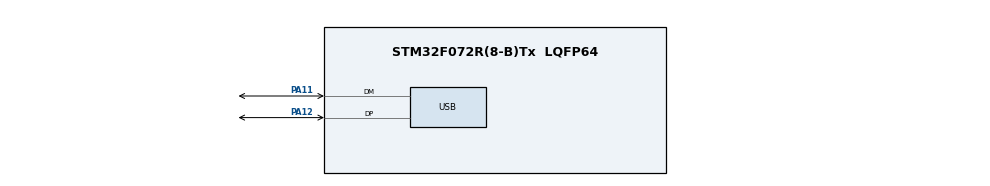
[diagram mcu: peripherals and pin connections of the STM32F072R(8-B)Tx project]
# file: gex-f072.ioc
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FREERTOS.Tasks01=defaultTask,0,128,StartDefaultTask,Default,NULL
Mcu.Family=STM32F0
Mcu.Name=STM32F072R(8-B)Tx
Mcu.Package=LQFP64
NVIC.TIM1_BRK_UP_TRG_COM_IRQn=true\:0\:0\:false\:false\:true\:false\:false
NVIC.TimeBase=TIM1_BRK_UP_TRG_COM_IRQn
NVIC.TimeBaseIP=TIM1
PA11.Mode=Device
PA11.Signal=USB_DM
PA12.Mode=Device
PA12.Signal=USB_DP
PA13.Mode=Serial_Wire
PA13.Signal=SYS_SWDIO
PA14.Mode=Serial_Wire
PA14.Signal=SYS_SWCLK
PF0-OSC_IN.Mode=HSE-External-Clock-Source
PF0-OSC_IN.Signal=RCC_OSC_IN
ProjectManager.HeapSize=0x200
ProjectManager.StackSize=0x400
ProjectManager.TargetToolchain=Makefile
RCC.AHBFreq_Value=48000000
RCC.APB1Freq_Value=48000000
RCC.APB1TimFreq_Value=48000000
RCC.HCLKFreq_Value=48000000
RCC.PLLMUL=RCC_PLL_MUL6
RCC.PLLSourceVirtual=RCC_PLLSOURCE_HSE
RCC.SYSCLKFreq_VALUE=48000000
RCC.SYSCLKSource=RCC_SYSCLKSOURCE_PLLCLK
VP_FREERTOS_VS_ENABLE.Mode=Enabled
VP_SYS_VS_tim1.Mode=TIM1
board=gex-f072

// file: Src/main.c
/**
  ******************************************************************************
  * File Name          : main.c
  * Description        : Main program body
  ******************************************************************************
  * This notice applies to any and all portions of this file
  * that are not between comment pairs USER CODE BEGIN and
  * USER CODE END. Other portions of this file, whether
  * inserted by the user or by software development tools
  * are owned by their respective copyright owners.
  *
  * Copyright (c) 2017 STMicroelectronics International N.V.
  * All rights reserved.
  *
  * Redistribution and use in source and binary forms, with or without
  * modification, are permitted, provided that the following conditions are met:
  *
  * 1. Redistribution of source code must retain the above copyright notice,
  *    this list of conditions and the following disclaimer.
  * 2. Redistributions in binary form must reproduce the above copyright notice,
  *    this list of conditions and the following disclaimer in the documentation
  *    and/or other materials provided with the distribution.
  * 3. Neither the name of STMicroelectronics nor the names of other
  *    contributors to this software may be used to endorse or promote products
  *    derived from this software without specific written permission.
  * 4. This software, including modifications and/or derivative works of this
  *    software, must execute solely and exclusively on microcontroller or
  *    microprocessor devices manufactured by or for STMicroelectronics.
  * 5. Redistribution and use of this software other than as permitted under
  *    this license is void and will automatically terminate your rights under
  *    this license.
  *
  * THIS SOFTWARE IS PROVIDED BY STMICROELECTRONICS AND CONTRIBUTORS "AS IS"
  * AND ANY EXPRESS, IMPLIED OR STATUTORY WARRANTIES, INCLUDING, BUT NOT
  * LIMITED TO, THE IMPLIED WARRANTIES OF MERCHANTABILITY, FITNESS FOR A
  * PARTICULAR PURPOSE AND NON-INFRINGEMENT OF THIRD PARTY INTELLECTUAL PROPERTY
  * RIGHTS ARE DISCLAIMED TO THE FULLEST EXTENT PERMITTED BY LAW. IN NO EVENT
  * SHALL STMICROELECTRONICS OR CONTRIBUTORS BE LIABLE FOR ANY DIRECT, INDIRECT,
  * INCIDENTAL, SPECIAL, EXEMPLARY, OR CONSEQUENTIAL DAMAGES (INCLUDING, BUT NOT
  * LIMITED TO, PROCUREMENT OF SUBSTITUTE GOODS OR SERVICES; LOSS OF USE, DATA,
  * OR PROFITS; OR BUSINESS INTERRUPTION) HOWEVER CAUSED AND ON ANY THEORY OF
  * LIABILITY, WHETHER IN CONTRACT, STRICT LIABILITY, OR TORT (INCLUDING
  * NEGLIGENCE OR OTHERWISE) ARISING IN ANY WAY OUT OF THE USE OF THIS SOFTWARE,
  * EVEN IF ADVISED OF THE POSSIBILITY OF SUCH DAMAGE.
  *
  ******************************************************************************
  */

#include "main.h"
#include "stm32f0xx_hal.h"
#include "cmsis_os.h"
#include <stdbool.h>

/* USER CODE BEGIN Includes */
#include "gex_hooks.h"
/* USER CODE END Includes */

/* USER CODE BEGIN PV */
/* Private variables ---------------------------------------------------------*/

/* USER CODE END PV */

void SystemClock_Config(void);
void MX_FREERTOS_Init(void);

/* USER CODE BEGIN PFP */
/* Private function prototypes -----------------------------------------------*/

/* USER CODE END PFP */

int main(void)
{

  /* MCU Configuration----------------------------------------------------------*/

  /* Reset of all peripherals, Initializes the Flash interface and the Systick. */
  HAL_Init();

  /* Configure the system clock */
  SystemClock_Config();

  /* Initialize all configured peripherals */
  GEX_PreInit();

  /* Call init function for freertos objects (in freertos.c) */
  MX_FREERTOS_Init();

  /* Start scheduler */
  osKernelStart();

  /* We should never get here as control is now taken by the scheduler */

  /* Infinite loop */
  while (1)
  {

  }

}

/** System Clock Configuration
*/
void SystemClock_Config(void)
{

  RCC_OscInitTypeDef RCC_OscInitStruct;
  RCC_ClkInitTypeDef RCC_ClkInitStruct;
  RCC_PeriphCLKInitTypeDef PeriphClkInit;

#if 0
    /**Initializes the CPU, AHB and APB busses clocks
    */
  RCC_OscInitStruct.OscillatorType = RCC_OSCILLATORTYPE_HSI48|RCC_OSCILLATORTYPE_HSE;
  RCC_OscInitStruct.HSEState = RCC_HSE_BYPASS;
  RCC_OscInitStruct.HSI48State = RCC_HSI48_ON;
  RCC_OscInitStruct.PLL.PLLState = RCC_PLL_ON;
  RCC_OscInitStruct.PLL.PLLSource = RCC_PLLSOURCE_HSE;
  RCC_OscInitStruct.PLL.PLLMUL = RCC_PLL_MUL6;
  RCC_OscInitStruct.PLL.PREDIV = RCC_PREDIV_DIV1;
  if (HAL_RCC_OscConfig(&RCC_OscInitStruct) != HAL_OK)
  {
    _Error_Handler(__FILE__, __LINE__);
  }
#else
  volatile uint32_t counter;

  /* Set FLASH latency */
  LL_FLASH_SetLatency(LL_FLASH_LATENCY_1);

#if !PLAT_FULL_XTAL
  LL_RCC_HSE_EnableBypass();
#endif

  LL_RCC_HSE_Enable();
  counter = 0;
  while(LL_RCC_HSE_IsReady() != 1 && counter < 10000) {
    counter++;
  }

  bool has_pll = 0;
  if (LL_RCC_HSE_IsReady() == 0) {

    // Looks like HSE xtal doesn't work - use HSI48
    LL_RCC_HSI48_Enable();
    while(LL_RCC_HSI48_IsReady() != 1) {}

    LL_CRS_EnableAutoTrimming(); // crystalless USB

    LL_RCC_SetAHBPrescaler(LL_RCC_SYSCLK_DIV_1);
    LL_RCC_SetSysClkSource(LL_RCC_SYS_CLKSOURCE_HSI48);
    while(LL_RCC_GetSysClkSource() != LL_RCC_SYS_CLKSOURCE_STATUS_HSI48) {}

  } else {
    // external 8 MHz xtal

    /* Main PLL configuration and activation */
    LL_RCC_PLL_ConfigDomain_SYS(LL_RCC_PLLSOURCE_HSE, LL_RCC_PLL_MUL_6, LL_RCC_PREDIV_DIV_1);

    LL_RCC_PLL_Enable();
    while(LL_RCC_PLL_IsReady() != 1) {}

    /* Sysclk activation on the main PLL */
    LL_RCC_SetAHBPrescaler(LL_RCC_SYSCLK_DIV_1);
    LL_RCC_SetSysClkSource(LL_RCC_SYS_CLKSOURCE_PLL);
    while(LL_RCC_GetSysClkSource() != LL_RCC_SYS_CLKSOURCE_STATUS_PLL) {}

      has_pll = true;
  }

  /* Set APB1 prescaler */
  LL_RCC_SetAPB1Prescaler(LL_RCC_APB1_DIV_1);

  /* Update CMSIS variable (which can be updated also through SystemCoreClockUpdate function) */
  LL_SetSystemCoreClock(48000000);
#endif

  // TODO this can be rewritten using LL while greatly reducing code size

    /**Initializes the CPU, AHB and APB busses clocks
    */
  RCC_ClkInitStruct.ClockType = RCC_CLOCKTYPE_HCLK|RCC_CLOCKTYPE_SYSCLK|RCC_CLOCKTYPE_PCLK1;
  RCC_ClkInitStruct.SYSCLKSource = has_pll ? RCC_SYSCLKSOURCE_PLLCLK : RCC_SYSCLKSOURCE_HSI48;
  RCC_ClkInitStruct.AHBCLKDivider = RCC_SYSCLK_DIV1;
  RCC_ClkInitStruct.APB1CLKDivider = RCC_HCLK_DIV1;

  if (HAL_RCC_ClockConfig(&RCC_ClkInitStruct, FLASH_LATENCY_1) != HAL_OK)
  {
    _Error_Handler(__FILE__, __LINE__);
  }

  PeriphClkInit.PeriphClockSelection = RCC_PERIPHCLK_USB;
  PeriphClkInit.UsbClockSelection = RCC_USBCLKSOURCE_HSI48;

  if (HAL_RCCEx_PeriphCLKConfig(&PeriphClkInit) != HAL_OK)
  {
    _Error_Handler(__FILE__, __LINE__);
  }

    /**Configure the Systick interrupt time
    */
  HAL_SYSTICK_Config(HAL_RCC_GetHCLKFreq()/1000);

    /**Configure the Systick
    */
  HAL_SYSTICK_CLKSourceConfig(SYSTICK_CLKSOURCE_HCLK);

  /* SysTick_IRQn interrupt configuration */
  HAL_NVIC_SetPriority(SysTick_IRQn, 3, 0);
}

//
///**
//  * @brief  Period elapsed callback in non blocking mode
//  * @note   This function is called  when TIM1 interrupt took place, inside
//  * HAL_TIM_IRQHandler(). It makes a direct call to HAL_IncTick() to increment
//  * a global variable "uwTick" used as application time base.
//  * @param  htim : TIM handle
//  * @retval None
//  */
//void HAL_TIM_PeriodElapsedCallback(TIM_HandleTypeDef *htim)
//{
///* USER CODE BEGIN Callback 0 */
//
///* USER CODE END Callback 0 */
//  if (htim->Instance == TIM1) {
//    HAL_IncTick();
//  }
///* USER CODE BEGIN Callback 1 */
//
///* USER CODE END Callback 1 */
//}
//

/************************ (C) COPYRIGHT STMicroelectronics *****END OF FILE****/
